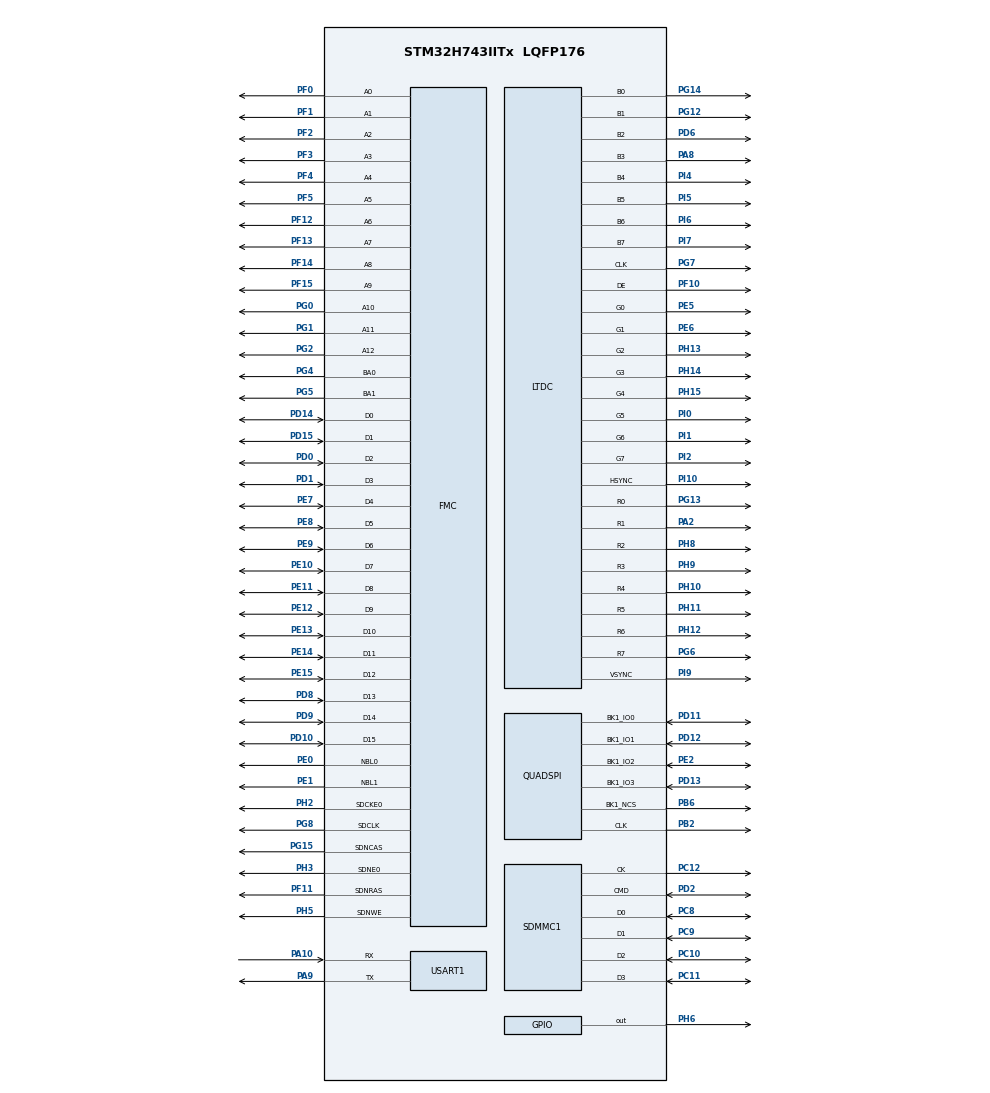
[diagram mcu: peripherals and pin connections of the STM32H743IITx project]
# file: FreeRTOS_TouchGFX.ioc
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CORTEX_M7.AccessPermission-Cortex_Memory_Protection_Unit_Region0_Settings=MPU_REGION_FULL_ACCESS
CORTEX_M7.BaseAddress-Cortex_Memory_Protection_Unit_Region0_Settings=0xC0000000
CORTEX_M7.CPU_DCache=Enabled
CORTEX_M7.CPU_ICache=Enabled
CORTEX_M7.Enable-Cortex_Memory_Protection_Unit_Region0_Settings=MPU_REGION_ENABLE
CORTEX_M7.IsCacheable-Cortex_Memory_Protection_Unit_Region0_Settings=MPU_ACCESS_CACHEABLE
CORTEX_M7.MPU_Control=MPU_PRIVILEGED_DEFAULT
CORTEX_M7.Size-Cortex_Memory_Protection_Unit_Region0_Settings=MPU_REGION_SIZE_32MB
DMA2D.ColorMode=DMA2D_OUTPUT_RGB565
DMA2D.Mode=DMA2D_M2M
Dma.Request0=USART1_RX
Dma.Request1=USART1_TX
Dma.USART1_RX.0.Direction=DMA_PERIPH_TO_MEMORY
Dma.USART1_RX.0.EventEnable=DISABLE
Dma.USART1_RX.0.FIFOMode=DMA_FIFOMODE_DISABLE
Dma.USART1_RX.0.Instance=DMA1_Stream0
Dma.USART1_RX.0.MemDataAlignment=DMA_MDATAALIGN_BYTE
Dma.USART1_RX.0.MemInc=DMA_MINC_ENABLE
Dma.USART1_RX.0.Mode=DMA_NORMAL
Dma.USART1_RX.0.PeriphDataAlignment=DMA_PDATAALIGN_BYTE
Dma.USART1_RX.0.PeriphInc=DMA_PINC_DISABLE
Dma.USART1_RX.0.Polarity=HAL_DMAMUX_REQ_GEN_RISING
Dma.USART1_RX.0.Priority=DMA_PRIORITY_LOW
Dma.USART1_RX.0.RequestNumber=1
Dma.USART1_RX.0.SignalID=NONE
Dma.USART1_RX.0.SyncEnable=DISABLE
Dma.USART1_RX.0.SyncPolarity=HAL_DMAMUX_SYNC_NO_EVENT
Dma.USART1_RX.0.SyncRequestNumber=1
Dma.USART1_RX.0.SyncSignalID=NONE
Dma.USART1_TX.1.Direction=DMA_MEMORY_TO_PERIPH
Dma.USART1_TX.1.EventEnable=DISABLE
Dma.USART1_TX.1.FIFOMode=DMA_FIFOMODE_DISABLE
Dma.USART1_TX.1.Instance=DMA1_Stream1
Dma.USART1_TX.1.MemDataAlignment=DMA_MDATAALIGN_BYTE
Dma.USART1_TX.1.MemInc=DMA_MINC_ENABLE
Dma.USART1_TX.1.Mode=DMA_NORMAL
Dma.USART1_TX.1.PeriphDataAlignment=DMA_PDATAALIGN_BYTE
Dma.USART1_TX.1.PeriphInc=DMA_PINC_DISABLE
Dma.USART1_TX.1.Polarity=HAL_DMAMUX_REQ_GEN_RISING
Dma.USART1_TX.1.Priority=DMA_PRIORITY_LOW
Dma.USART1_TX.1.RequestNumber=1
Dma.USART1_TX.1.SignalID=NONE
Dma.USART1_TX.1.SyncEnable=DISABLE
Dma.USART1_TX.1.SyncPolarity=HAL_DMAMUX_SYNC_NO_EVENT
Dma.USART1_TX.1.SyncRequestNumber=1
Dma.USART1_TX.1.SyncSignalID=NONE
FATFS._CODE_PAGE=437
FATFS._FS_EXFAT=1
FATFS._MAX_SS=4096
FATFS._USE_LFN=2
FMC.CASLatency1=FMC_SDRAM_CAS_LATENCY_3
FMC.ColumnBitsNumber1=FMC_SDRAM_COLUMN_BITS_NUM_9
FMC.ExitSelfRefreshDelay1=7
FMC.LoadToActiveDelay1=2
FMC.RCDDelay1=2
FMC.RPDelay1=2
FMC.ReadBurst1=FMC_SDRAM_RBURST_ENABLE
FMC.ReadPipeDelay1=FMC_SDRAM_RPIPE_DELAY_1
FMC.RowCycleDelay1=7
FMC.SDClockPeriod1=FMC_SDRAM_CLOCK_PERIOD_2
FMC.SelfRefreshTime1=4
FMC.WriteRecoveryTime1=3
FREERTOS.Tasks01=defaultTask,24,2048,StartDefaultTask,Default,NULL,Dynamic,NULL,NULL
FREERTOS.configTOTAL_HEAP_SIZE=32768
LTDC.ActiveW=800
LTDC.Alpha_L0=255
LTDC.FBStartAdress_L0=0xC0000000
LTDC.HBP=80
LTDC.HFP=200
LTDC.HSync=1
LTDC.ImageHeight_L0=480
LTDC.ImageWidth_L0=800
LTDC.Layers=0
LTDC.PixelFormat_L0=LTDC_PIXEL_FORMAT_RGB565
LTDC.VBP=40
LTDC.VFP=22
LTDC.VSync=1
LTDC.WindowX1_L0=800
LTDC.WindowY1_L0=480
Mcu.Family=STM32H7
Mcu.Name=STM32H743IITx
Mcu.Package=LQFP176
Mdma.MDMA_Channel0.Request0=SDMMC1_END_DATA
Mdma.MDMA_Channel0.RequestsNb=1
Mdma.MDMA_Channel0.SDMMC1_END_DATA.0.BlockCount=0
Mdma.MDMA_Channel0.SDMMC1_END_DATA.0.BlockDataLength=0
Mdma.MDMA_Channel0.SDMMC1_END_DATA.0.BufferTransferLength=1
Mdma.MDMA_Channel0.SDMMC1_END_DATA.0.CircularMode=MDMA_LINEAR_LIST
Mdma.MDMA_Channel0.SDMMC1_END_DATA.0.DataAlignment=MDMA_DATAALIGN_PACKENABLE
Mdma.MDMA_Channel0.SDMMC1_END_DATA.0.DestBlockAddressOffset=0
Mdma.MDMA_Channel0.SDMMC1_END_DATA.0.DestBurst=MDMA_DEST_BURST_SINGLE
Mdma.MDMA_Channel0.SDMMC1_END_DATA.0.DestDataSize=MDMA_DEST_DATASIZE_BYTE
Mdma.MDMA_Channel0.SDMMC1_END_DATA.0.DestinationInc=MDMA_DEST_INC_BYTE
Mdma.MDMA_Channel0.SDMMC1_END_DATA.0.DstAddress=0
Mdma.MDMA_Channel0.SDMMC1_END_DATA.0.Endianness=MDMA_LITTLE_ENDIANNESS_PRESERVE
Mdma.MDMA_Channel0.SDMMC1_END_DATA.0.Instance=MDMA_Channel0
Mdma.MDMA_Channel0.SDMMC1_END_DATA.0.MaskAddress=0
Mdma.MDMA_Channel0.SDMMC1_END_DATA.0.MaskData=0
Mdma.MDMA_Channel0.SDMMC1_END_DATA.0.Priority=MDMA_PRIORITY_LOW
Mdma.MDMA_Channel0.SDMMC1_END_DATA.0.Rank=First
Mdma.MDMA_Channel0.SDMMC1_END_DATA.0.SourceBlockAddressOffset=0
Mdma.MDMA_Channel0.SDMMC1_END_DATA.0.SourceBurst=MDMA_SOURCE_BURST_SINGLE
Mdma.MDMA_Channel0.SDMMC1_END_DATA.0.SourceDataSize=MDMA_SRC_DATASIZE_BYTE
Mdma.MDMA_Channel0.SDMMC1_END_DATA.0.SourceInc=MDMA_SRC_INC_BYTE
Mdma.MDMA_Channel0.SDMMC1_END_DATA.0.SrcAddress=0
Mdma.MDMA_Channel0.SDMMC1_END_DATA.0.TransferTriggerMode=MDMA_BUFFER_TRANSFER
Mdma.RequestSet0=MDMA_Channel0
Mdma.RequestSetsNb=1
NVIC.DMA1_Stream0_IRQn=true\:5\:0\:false\:false\:true\:true\:false\:true\:true
NVIC.DMA1_Stream1_IRQn=true\:5\:0\:false\:false\:true\:true\:false\:true\:true
NVIC.DMA2D_IRQn=true\:5\:0\:false\:false\:true\:true\:true\:true\:true
NVIC.FMC_IRQn=true\:5\:0\:false\:false\:true\:true\:true\:true\:true
NVIC.LTDC_ER_IRQn=true\:5\:0\:false\:false\:true\:true\:true\:true\:true
NVIC.LTDC_IRQn=true\:5\:0\:false\:false\:true\:true\:true\:true\:true
NVIC.MDMA_IRQn=true\:5\:0\:false\:false\:true\:false\:false\:true\:true
NVIC.PriorityGroup=NVIC_PRIORITYGROUP_4
NVIC.SDMMC1_IRQn=true\:7\:0\:true\:false\:true\:true\:true\:true\:true
PA10.Mode=Asynchronous
PA10.Signal=USART1_RX
PA13\ (JTMS/SWDIO).Mode=Serial_Wire
PA13\ (JTMS/SWDIO).Signal=DEBUG_JTMS-SWDIO
PA14\ (JTCK/SWCLK).Mode=Serial_Wire
PA14\ (JTCK/SWCLK).Signal=DEBUG_JTCK-SWCLK
PA2.GPIO_Speed=GPIO_SPEED_FREQ_VERY_HIGH
PA2.Mode=RGB888
PA2.Signal=LTDC_R1
PA8.GPIO_Speed=GPIO_SPEED_FREQ_VERY_HIGH
PA8.Mode=RGB888
PA8.Signal=LTDC_B3
PA9.Mode=Asynchronous
PA9.Signal=USART1_TX
PB2.GPIO_Speed=GPIO_SPEED_FREQ_VERY_HIGH
PB2.Mode=Single Bank 1
PB2.Signal=QUADSPI_CLK
PB6.GPIO_Speed=GPIO_SPEED_FREQ_VERY_HIGH
PB6.Mode=Single Bank 1
PB6.Signal=QUADSPI_BK1_NCS
PC10.GPIO_PuPd=GPIO_PULLUP
PC10.Mode=SD_4_bits_Wide_bus
PC10.Signal=SDMMC1_D2
PC11.GPIO_PuPd=GPIO_PULLUP
PC11.Mode=SD_4_bits_Wide_bus
PC11.Signal=SDMMC1_D3
PC12.Mode=SD_4_bits_Wide_bus
PC12.Signal=SDMMC1_CK
PC14-OSC32_IN\ (OSC32_IN).Mode=LSE-External-Oscillator
PC14-OSC32_IN\ (OSC32_IN).Signal=RCC_OSC32_IN
PC15-OSC32_OUT\ (OSC32_OUT).Mode=LSE-External-Oscillator
PC15-OSC32_OUT\ (OSC32_OUT).Signal=RCC_OSC32_OUT
PC8.GPIO_PuPd=GPIO_PULLUP
PC8.Mode=SD_4_bits_Wide_bus
PC8.Signal=SDMMC1_D0
PC9.GPIO_PuPd=GPIO_PULLUP
PC9.Mode=SD_4_bits_Wide_bus
PC9.Signal=SDMMC1_D1
PD0.Signal=FMC_D2_DA2
PD1.Signal=FMC_D3_DA3
PD10.Signal=FMC_D15_DA15
PD11.GPIO_Speed=GPIO_SPEED_FREQ_VERY_HIGH
PD11.Mode=Single Bank 1
PD11.Signal=QUADSPI_BK1_IO0
PD12.GPIO_Speed=GPIO_SPEED_FREQ_VERY_HIGH
PD12.Mode=Single Bank 1
PD12.Signal=QUADSPI_BK1_IO1
PD13.GPIO_Speed=GPIO_SPEED_FREQ_VERY_HIGH
PD13.Mode=Single Bank 1
PD13.Signal=QUADSPI_BK1_IO3
PD14.Signal=FMC_D0_DA0
PD15.Signal=FMC_D1_DA1
PD2.GPIO_PuPd=GPIO_PULLUP
PD2.Mode=SD_4_bits_Wide_bus
PD2.Signal=SDMMC1_CMD
PD6.GPIO_Speed=GPIO_SPEED_FREQ_VERY_HIGH
PD6.Mode=RGB888
PD6.Signal=LTDC_B2
PD8.Signal=FMC_D13_DA13
PD9.Signal=FMC_D14_DA14
PE0.Signal=FMC_NBL0
PE1.Signal=FMC_NBL1
PE10.Signal=FMC_D7_DA7
PE11.Signal=FMC_D8_DA8
PE12.Signal=FMC_D9_DA9
PE13.Signal=FMC_D10_DA10
PE14.Signal=FMC_D11_DA11
PE15.Signal=FMC_D12_DA12
PE2.GPIO_Speed=GPIO_SPEED_FREQ_VERY_HIGH
PE2.Mode=Single Bank 1
PE2.Signal=QUADSPI_BK1_IO2
PE5.GPIO_Speed=GPIO_SPEED_FREQ_VERY_HIGH
PE5.Mode=RGB888
PE5.Signal=LTDC_G0
PE6.GPIO_Speed=GPIO_SPEED_FREQ_VERY_HIGH
PE6.Mode=RGB888
PE6.Signal=LTDC_G1
PE7.Signal=FMC_D4_DA4
PE8.Signal=FMC_D5_DA5
PE9.Signal=FMC_D6_DA6
PF0.Signal=FMC_A0
PF1.Signal=FMC_A1
PF10.GPIO_Speed=GPIO_SPEED_FREQ_VERY_HIGH
PF10.Mode=RGB888
PF10.Signal=LTDC_DE
PF11.Signal=FMC_SDNRAS
PF12.Signal=FMC_A6
PF13.Signal=FMC_A7
PF14.Signal=FMC_A8
PF15.Signal=FMC_A9
PF2.Signal=FMC_A2
PF3.Signal=FMC_A3
PF4.Signal=FMC_A4
PF5.Signal=FMC_A5
PG0.Signal=FMC_A10
PG1.Signal=FMC_A11
PG12.GPIO_Speed=GPIO_SPEED_FREQ_VERY_HIGH
PG12.Mode=RGB888
PG12.Signal=LTDC_B1
PG13.GPIO_Speed=GPIO_SPEED_FREQ_VERY_HIGH
PG13.Mode=RGB888
PG13.Signal=LTDC_R0
PG14.GPIO_Speed=GPIO_SPEED_FREQ_VERY_HIGH
PG14.Mode=RGB888
PG14.Signal=LTDC_B0
PG15.Signal=FMC_SDNCAS
PG2.Signal=FMC_A12
PG4.Signal=FMC_A14_BA0
PG5.Signal=FMC_A15_BA1
PG6.GPIO_Speed=GPIO_SPEED_FREQ_VERY_HIGH
PG6.Mode=RGB888
PG6.Signal=LTDC_R7
PG7.GPIO_Speed=GPIO_SPEED_FREQ_VERY_HIGH
PG7.Mode=RGB888
PG7.Signal=LTDC_CLK
PG8.Signal=FMC_SDCLK
PH0-OSC_IN\ (PH0).Mode=HSE-External-Oscillator
PH0-OSC_IN\ (PH0).Signal=RCC_OSC_IN
PH1-OSC_OUT\ (PH1).Mode=HSE-External-Oscillator
PH1-OSC_OUT\ (PH1).Signal=RCC_OSC_OUT
PH10.GPIO_Speed=GPIO_SPEED_FREQ_VERY_HIGH
PH10.Mode=RGB888
PH10.Signal=LTDC_R4
PH11.GPIO_Speed=GPIO_SPEED_FREQ_VERY_HIGH
PH11.Mode=RGB888
PH11.Signal=LTDC_R5
PH12.GPIO_Speed=GPIO_SPEED_FREQ_VERY_HIGH
PH12.Mode=RGB888
PH12.Signal=LTDC_R6
PH13.GPIO_Speed=GPIO_SPEED_FREQ_VERY_HIGH
PH13.Mode=RGB888
PH13.Signal=LTDC_G2
PH14.GPIO_Speed=GPIO_SPEED_FREQ_VERY_HIGH
PH14.Mode=RGB888
PH14.Signal=LTDC_G3
PH15.GPIO_Speed=GPIO_SPEED_FREQ_VERY_HIGH
PH15.Mode=RGB888
PH15.Signal=LTDC_G4
PH2.Mode=SdramChipSelect1_1
PH2.Signal=FMC_SDCKE0
PH3.Mode=SdramChipSelect1_1
PH3.Signal=FMC_SDNE0
PH5.Signal=FMC_SDNWE
PH6.PinState=GPIO_PIN_SET
PH6.Signal=GPIO_Output
PH8.GPIO_Speed=GPIO_SPEED_FREQ_VERY_HIGH
PH8.Mode=RGB888
PH8.Signal=LTDC_R2
PH9.GPIO_Speed=GPIO_SPEED_FREQ_VERY_HIGH
PH9.Mode=RGB888
PH9.Signal=LTDC_R3
PI0.GPIO_Speed=GPIO_SPEED_FREQ_VERY_HIGH
PI0.Mode=RGB888
PI0.Signal=LTDC_G5
PI1.GPIO_Speed=GPIO_SPEED_FREQ_VERY_HIGH
PI1.Mode=RGB888
PI1.Signal=LTDC_G6
PI10.GPIO_Speed=GPIO_SPEED_FREQ_VERY_HIGH
PI10.Mode=RGB888
PI10.Signal=LTDC_HSYNC
PI2.GPIO_Speed=GPIO_SPEED_FREQ_VERY_HIGH
PI2.Mode=RGB888
PI2.Signal=LTDC_G7
PI4.GPIO_Speed=GPIO_SPEED_FREQ_VERY_HIGH
PI4.Mode=RGB888
PI4.Signal=LTDC_B4
PI5.GPIO_Speed=GPIO_SPEED_FREQ_VERY_HIGH
PI5.Mode=RGB888
PI5.Signal=LTDC_B5
PI6.GPIO_Speed=GPIO_SPEED_FREQ_VERY_HIGH
PI6.Mode=RGB888
PI6.Signal=LTDC_B6
PI7.GPIO_Speed=GPIO_SPEED_FREQ_VERY_HIGH
PI7.Mode=RGB888
PI7.Signal=LTDC_B7
PI9.GPIO_Speed=GPIO_SPEED_FREQ_VERY_HIGH
PI9.Mode=RGB888
PI9.Signal=LTDC_VSYNC
ProjectManager.HeapSize=0x2000
ProjectManager.StackSize=0x1000
ProjectManager.TargetToolchain=STM32CubeIDE
QUADSPI.ClockMode=QSPI_CLOCK_MODE_3
QUADSPI.ClockPrescaler=1
QUADSPI.FifoThreshold=32
QUADSPI.FlashSize=22
QUADSPI.SampleShifting=QSPI_SAMPLE_SHIFTING_HALFCYCLE
RCC.ADCFreq_Value=50390625
RCC.APB1Freq_Value=120000000
RCC.APB2Freq_Value=120000000
RCC.APB3Freq_Value=120000000
RCC.APB4Freq_Value=120000000
RCC.CortexFreq_Value=480000000
RCC.D1PPRE=RCC_APB3_DIV2
RCC.D2PPRE1=RCC_APB1_DIV2
RCC.D2PPRE2=RCC_APB2_DIV2
RCC.D3PPRE=RCC_APB4_DIV2
RCC.DIVM1=5
RCC.DIVM3=25
RCC.DIVN1=192
RCC.DIVN3=330
RCC.DIVQ1=4
RCC.DIVR3=10
RCC.HCLKFreq_Value=240000000
RCC.HPRE=RCC_HCLK_DIV2
RCC.PLLSourceVirtual=RCC_PLLSOURCE_HSE
RCC.ProductRev=revV
RCC.RTCClockSelection=RCC_RTCCLKSOURCE_LSE
RCC.SYSCLKFreq_VALUE=480000000
RCC.SYSCLKSource=RCC_SYSCLKSOURCE_PLLCLK
RCC.USBFreq_Value=240000000
SDMMC1.ClockDiv=6
SH.FMC_A0.0=FMC_A0,13b-sda1
SH.FMC_A1.0=FMC_A1,13b-sda1
SH.FMC_A10.0=FMC_A10,13b-sda1
SH.FMC_A11.0=FMC_A11,13b-sda1
SH.FMC_A12.0=FMC_A12,13b-sda1
SH.FMC_A14_BA0.0=FMC_BA0,FourSdramBanks1
SH.FMC_A15_BA1.0=FMC_BA1,FourSdramBanks1
SH.FMC_A2.0=FMC_A2,13b-sda1
SH.FMC_A3.0=FMC_A3,13b-sda1
SH.FMC_A4.0=FMC_A4,13b-sda1
SH.FMC_A5.0=FMC_A5,13b-sda1
SH.FMC_A6.0=FMC_A6,13b-sda1
SH.FMC_A7.0=FMC_A7,13b-sda1
SH.FMC_A8.0=FMC_A8,13b-sda1
SH.FMC_A9.0=FMC_A9,13b-sda1
SH.FMC_D0_DA0.0=FMC_D0,sd-16b-d1
SH.FMC_D10_DA10.0=FMC_D10,sd-16b-d1
SH.FMC_D11_DA11.0=FMC_D11,sd-16b-d1
SH.FMC_D12_DA12.0=FMC_D12,sd-16b-d1
SH.FMC_D13_DA13.0=FMC_D13,sd-16b-d1
SH.FMC_D14_DA14.0=FMC_D14,sd-16b-d1
SH.FMC_D15_DA15.0=FMC_D15,sd-16b-d1
SH.FMC_D1_DA1.0=FMC_D1,sd-16b-d1
SH.FMC_D2_DA2.0=FMC_D2,sd-16b-d1
SH.FMC_D3_DA3.0=FMC_D3,sd-16b-d1
SH.FMC_D4_DA4.0=FMC_D4,sd-16b-d1
SH.FMC_D5_DA5.0=FMC_D5,sd-16b-d1
SH.FMC_D6_DA6.0=FMC_D6,sd-16b-d1
SH.FMC_D7_DA7.0=FMC_D7,sd-16b-d1
SH.FMC_D8_DA8.0=FMC_D8,sd-16b-d1
SH.FMC_D9_DA9.0=FMC_D9,sd-16b-d1
SH.FMC_NBL0.0=FMC_NBL0,Sd2ByteEnable1
SH.FMC_NBL1.0=FMC_NBL1,Sd2ByteEnable1
SH.FMC_SDCLK.0=FMC_SDCLK,13b-sda1
SH.FMC_SDNCAS.0=FMC_SDNCAS,13b-sda1
SH.FMC_SDNRAS.0=FMC_SDNRAS,13b-sda1
SH.FMC_SDNWE.0=FMC_SDNWE,13b-sda1
STMicroelectronics.X-CUBE-TOUCHGFX.4.24.1.ApplicationCcGraphicsJjApplication=TouchGFXOoGenerator
STMicroelectronics.X-CUBE-TOUCHGFX.4.24.1.tgfx_address1=0xC0000000
STMicroelectronics.X-CUBE-TOUCHGFX.4.24.1.tgfx_address2=0xC00BB800
STMicroelectronics.X-CUBE-TOUCHGFX.4.24.1.tgfx_buffering_strategy=Double
STMicroelectronics.X-CUBE-TOUCHGFX.4.24.1.tgfx_custom_height=480
STMicroelectronics.X-CUBE-TOUCHGFX.4.24.1.tgfx_display_interface=disp_ltdc
STMicroelectronics.X-CUBE-TOUCHGFX.4.24.1.tgfx_hardware_accelerator=dma_2d
STMicroelectronics.X-CUBE-TOUCHGFX.4.24.1.tgfx_location=By Address
STMicroelectronics.X-CUBE-TOUCHGFX.4.24.1.tgfx_vsync=vsync_ltdc
STMicroelectronics.X-CUBE-TOUCHGFX.4.24.1_IsPackSelfContextualization=true
USART1.VirtualMode-Asynchronous=VM_ASYNC
VP_CRC_VS_CRC.Mode=CRC_Activate
VP_DMA2D_VS_DMA2D.Mode=DMA2D_Activate
VP_FATFS_VS_SDIO.Mode=SDIO
VP_FREERTOS_VS_CMSIS_V2.Mode=CMSIS_V2
VP_MEMORYMAP_VS_MEMORYMAP.Mode=CurAppReg
VP_RTC_VS_RTC_Activate.Mode=RTC_Enabled
VP_STMicroelectronics.X-CUBE-TOUCHGFX_VS_GraphicsJjApplication_4.24.1.Mode=GraphicsJjApplication
board=custom

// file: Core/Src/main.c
/* USER CODE BEGIN Header */
/**
  ******************************************************************************
  * @file           : main.c
  * @brief          : Main program body
  ******************************************************************************
  * @attention
  *
  * Copyright (c) 2025 STMicroelectronics.
  * All rights reserved.
  *
  * This software is licensed under terms that can be found in the LICENSE file
  * in the root directory of this software component.
  * If no LICENSE file comes with this software, it is provided AS-IS.
  *
  ******************************************************************************
  */
/* USER CODE END Header */
#include "main.h"
#include "cmsis_os.h"
#include "crc.h"
#include "dma.h"
#include "dma2d.h"
#include "fatfs.h"
#include "ltdc.h"
#include "mdma.h"
#include "memorymap.h"
#include "quadspi.h"
#include "rtc.h"
#include "sdmmc.h"
#include "usart.h"
#include "gpio.h"
#include "fmc.h"

/* USER CODE BEGIN Includes */
#include <lcd_rgb.h>
#include "led.h"
/* USER CODE END Includes */

void SystemClock_Config(void);
static void MPU_Config(void);
void MX_FREERTOS_Init(void);
/* USER CODE BEGIN PFP */
void BSP_Init(void);
/* USER CODE END PFP */

int main(void)
{

  /* MPU Configuration--------------------------------------------------------*/
  MPU_Config();

  /* Enable the CPU Cache */

  /* Enable I-Cache---------------------------------------------------------*/
  SCB_EnableICache();

  /* Enable D-Cache---------------------------------------------------------*/
  SCB_EnableDCache();

  /* MCU Configuration--------------------------------------------------------*/

  /* Reset of all peripherals, Initializes the Flash interface and the Systick. */
  HAL_Init();

  /* Configure the system clock */
  SystemClock_Config();

  /* Initialize all configured peripherals */
  BSP_Init();

//  MX_TouchGFX_Init();
//  /* Call PreOsInit function */
//  MX_TouchGFX_PreOSInit();

  /* Init scheduler */
  osKernelInitialize();

  /* Call init function for freertos objects (in cmsis_os2.c) */
  MX_FREERTOS_Init();

  /* Start scheduler */
  osKernelStart();

  /* We should never get here as control is now taken by the scheduler */

  /* Infinite loop */
  while (1)
  {

  }
}

void SystemClock_Config(void)
{
  RCC_OscInitTypeDef RCC_OscInitStruct = {0};
  RCC_ClkInitTypeDef RCC_ClkInitStruct = {0};

  /** Supply configuration update enable
  */
  HAL_PWREx_ConfigSupply(PWR_LDO_SUPPLY);

  /** Configure the main internal regulator output voltage
  */
  __HAL_PWR_VOLTAGESCALING_CONFIG(PWR_REGULATOR_VOLTAGE_SCALE1);

  while(!__HAL_PWR_GET_FLAG(PWR_FLAG_VOSRDY)) {}

  __HAL_RCC_SYSCFG_CLK_ENABLE();
  __HAL_PWR_VOLTAGESCALING_CONFIG(PWR_REGULATOR_VOLTAGE_SCALE0);

  while(!__HAL_PWR_GET_FLAG(PWR_FLAG_VOSRDY)) {}

  /** Configure LSE Drive Capability
  */
  HAL_PWR_EnableBkUpAccess();
  __HAL_RCC_LSEDRIVE_CONFIG(RCC_LSEDRIVE_LOW);

  /** Initializes the RCC Oscillators according to the specified parameters
  * in the RCC_OscInitTypeDef structure.
  */
  RCC_OscInitStruct.OscillatorType = RCC_OSCILLATORTYPE_HSE|RCC_OSCILLATORTYPE_LSE;
  RCC_OscInitStruct.HSEState = RCC_HSE_ON;
  RCC_OscInitStruct.LSEState = RCC_LSE_ON;
  RCC_OscInitStruct.PLL.PLLState = RCC_PLL_ON;
  RCC_OscInitStruct.PLL.PLLSource = RCC_PLLSOURCE_HSE;
  RCC_OscInitStruct.PLL.PLLM = 5;
  RCC_OscInitStruct.PLL.PLLN = 192;
  RCC_OscInitStruct.PLL.PLLP = 2;
  RCC_OscInitStruct.PLL.PLLQ = 4;
  RCC_OscInitStruct.PLL.PLLR = 2;
  RCC_OscInitStruct.PLL.PLLRGE = RCC_PLL1VCIRANGE_2;
  RCC_OscInitStruct.PLL.PLLVCOSEL = RCC_PLL1VCOWIDE;
  RCC_OscInitStruct.PLL.PLLFRACN = 0;
  if (HAL_RCC_OscConfig(&RCC_OscInitStruct) != HAL_OK)
  {
    Error_Handler();
  }

  /** Initializes the CPU, AHB and APB buses clocks
  */
  RCC_ClkInitStruct.ClockType = RCC_CLOCKTYPE_HCLK|RCC_CLOCKTYPE_SYSCLK
                              |RCC_CLOCKTYPE_PCLK1|RCC_CLOCKTYPE_PCLK2
                              |RCC_CLOCKTYPE_D3PCLK1|RCC_CLOCKTYPE_D1PCLK1;
  RCC_ClkInitStruct.SYSCLKSource = RCC_SYSCLKSOURCE_PLLCLK;
  RCC_ClkInitStruct.SYSCLKDivider = RCC_SYSCLK_DIV1;
  RCC_ClkInitStruct.AHBCLKDivider = RCC_HCLK_DIV2;
  RCC_ClkInitStruct.APB3CLKDivider = RCC_APB3_DIV2;
  RCC_ClkInitStruct.APB1CLKDivider = RCC_APB1_DIV2;
  RCC_ClkInitStruct.APB2CLKDivider = RCC_APB2_DIV2;
  RCC_ClkInitStruct.APB4CLKDivider = RCC_APB4_DIV2;

  if (HAL_RCC_ClockConfig(&RCC_ClkInitStruct, FLASH_LATENCY_4) != HAL_OK)
  {
    Error_Handler();
  }
}

/* USER CODE BEGIN 4 */
void BSP_Init(void)
{
	MX_GPIO_Init();
	MX_DMA_Init();
	MX_MDMA_Init();
	MX_RTC_Init();
	MX_USART1_UART_Init();
	MX_FMC_Init();
	MX_LTDC_Init();
	MX_QUADSPI_Init();
	MX_SDMMC1_SD_Init();
	MX_DMA2D_Init();
	MX_FATFS_Init();
	MX_CRC_Init();

	LED_Init();
}
/* USER CODE END 4 */

 /* MPU Configuration */

void MPU_Config(void)
{
  MPU_Region_InitTypeDef MPU_InitStruct = {0};

  /* Disables the MPU */
  HAL_MPU_Disable();

  /** Initializes and configures the Region and the memory to be protected
  */
  MPU_InitStruct.Enable = MPU_REGION_ENABLE;
  MPU_InitStruct.Number = MPU_REGION_NUMBER0;
  MPU_InitStruct.BaseAddress = SDRAM_BANK_ADDR;
  MPU_InitStruct.Size = MPU_REGION_SIZE_32MB;
  MPU_InitStruct.SubRegionDisable = 0x0;
  MPU_InitStruct.TypeExtField = MPU_TEX_LEVEL0;
  MPU_InitStruct.AccessPermission = MPU_REGION_FULL_ACCESS;
  MPU_InitStruct.DisableExec = MPU_INSTRUCTION_ACCESS_ENABLE;
  MPU_InitStruct.IsShareable = MPU_ACCESS_NOT_SHAREABLE;
  MPU_InitStruct.IsCacheable = MPU_ACCESS_CACHEABLE;
  MPU_InitStruct.IsBufferable = MPU_ACCESS_NOT_BUFFERABLE;

  HAL_MPU_ConfigRegion(&MPU_InitStruct);
  /* Enables the MPU */
  HAL_MPU_Enable(MPU_PRIVILEGED_DEFAULT);

}

void Error_Handler(void)
{
  __disable_irq();
  while (1)
  {
  }
}

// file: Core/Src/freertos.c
/* USER CODE BEGIN Header */
/**
  ******************************************************************************
  * File Name          : freertos.c
  * Description        : Code for freertos applications
  ******************************************************************************
  * @attention
  *
  * Copyright (c) 2025 STMicroelectronics.
  * All rights reserved.
  *
  * This software is licensed under terms that can be found in the LICENSE file
  * in the root directory of this software component.
  * If no LICENSE file comes with this software, it is provided AS-IS.
  *
  ******************************************************************************
  */
/* USER CODE END Header */

#include "FreeRTOS.h"
#include "task.h"
#include "main.h"
#include "cmsis_os.h"

/* USER CODE BEGIN Includes */
#include <stdio.h>
#include "fmc.h"
#include "app_touchgfx.h"
/* USER CODE END Includes */

/* Definitions for defaultTask */
osThreadId_t defaultTaskHandle;
const osThreadAttr_t defaultTask_attributes = {
  .name = "defaultTask",
  .stack_size = 2048 * 4,
  .priority = (osPriority_t) osPriorityNormal,
};

void StartDefaultTask(void *argument);

void MX_FREERTOS_Init(void); /* (MISRA C 2004 rule 8.1) */

void MX_FREERTOS_Init(void) {
  /* USER CODE BEGIN Init */
	printf("OS StartUp\n");
  /* USER CODE END Init */

  /* USER CODE BEGIN RTOS_QUEUES */
  /* add queues, ... */
	MX_TouchGFX_Init();
	/* Call PreOsInit function */
	MX_TouchGFX_PreOSInit();
//  SDRAM_Test();
  /* USER CODE END RTOS_QUEUES */

  /* Create the thread(s) */
  /* creation of defaultTask */
  defaultTaskHandle = osThreadNew(StartDefaultTask, NULL, &defaultTask_attributes);

}

void StartDefaultTask(void *argument)
{
  /* USER CODE BEGIN StartDefaultTask */
	printf("\033[34mDefaultTaskStart\033[0m\n");

//	MX_TouchGFX_Process();
	TouchGFX_Task(NULL);
  /* Infinite loop */
  for(;;)
  {
    osDelay(1);
  }
  /* USER CODE END StartDefaultTask */
}
